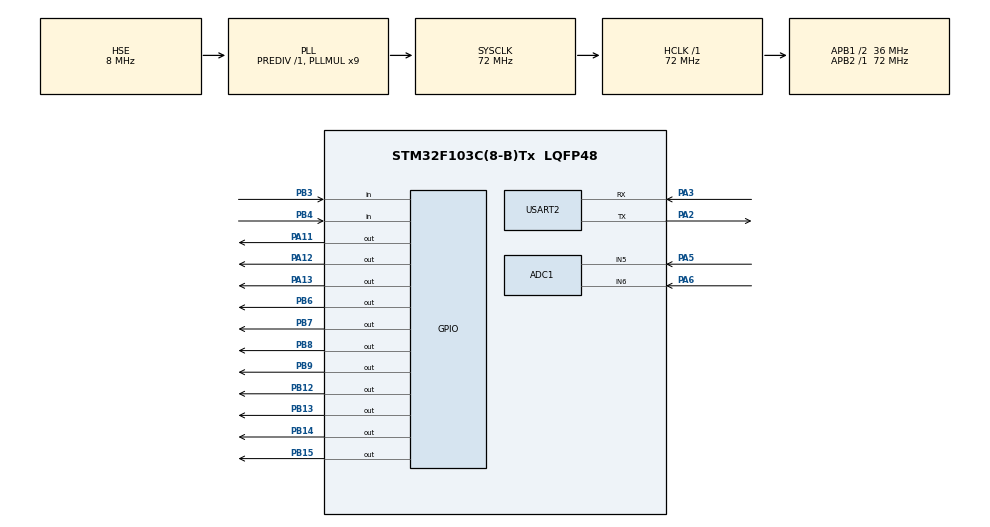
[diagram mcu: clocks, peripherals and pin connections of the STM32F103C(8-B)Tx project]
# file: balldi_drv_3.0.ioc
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ADC1.Channel-0\#ChannelRegularConversion=ADC_CHANNEL_5
ADC1.Channel-1\#ChannelRegularConversion=ADC_CHANNEL_6
ADC1.ContinuousConvMode=ENABLE
ADC1.NbrOfConversion=2
ADC1.NbrOfConversionFlag=1
ADC1.Rank-0\#ChannelRegularConversion=1
ADC1.Rank-1\#ChannelRegularConversion=2
ADC1.SamplingTime-0\#ChannelRegularConversion=ADC_SAMPLETIME_55CYCLES_5
ADC1.SamplingTime-1\#ChannelRegularConversion=ADC_SAMPLETIME_55CYCLES_5
ADC1.master=1
Dma.ADC1.2.Direction=DMA_PERIPH_TO_MEMORY
Dma.ADC1.2.Instance=DMA1_Channel1
Dma.ADC1.2.MemDataAlignment=DMA_MDATAALIGN_HALFWORD
Dma.ADC1.2.MemInc=DMA_MINC_ENABLE
Dma.ADC1.2.Mode=DMA_CIRCULAR
Dma.ADC1.2.PeriphDataAlignment=DMA_PDATAALIGN_HALFWORD
Dma.ADC1.2.PeriphInc=DMA_PINC_DISABLE
Dma.ADC1.2.Priority=DMA_PRIORITY_HIGH
Dma.Request0=USART2_RX
Dma.Request1=USART2_TX
Dma.Request2=ADC1
Dma.USART2_RX.0.Direction=DMA_PERIPH_TO_MEMORY
Dma.USART2_RX.0.Instance=DMA1_Channel6
Dma.USART2_RX.0.MemDataAlignment=DMA_MDATAALIGN_BYTE
Dma.USART2_RX.0.MemInc=DMA_MINC_ENABLE
Dma.USART2_RX.0.Mode=DMA_CIRCULAR
Dma.USART2_RX.0.PeriphDataAlignment=DMA_PDATAALIGN_BYTE
Dma.USART2_RX.0.PeriphInc=DMA_PINC_DISABLE
Dma.USART2_RX.0.Priority=DMA_PRIORITY_MEDIUM
Dma.USART2_TX.1.Direction=DMA_MEMORY_TO_PERIPH
Dma.USART2_TX.1.Instance=DMA1_Channel7
Dma.USART2_TX.1.MemDataAlignment=DMA_MDATAALIGN_BYTE
Dma.USART2_TX.1.MemInc=DMA_MINC_ENABLE
Dma.USART2_TX.1.Mode=DMA_NORMAL
Dma.USART2_TX.1.PeriphDataAlignment=DMA_PDATAALIGN_BYTE
Dma.USART2_TX.1.PeriphInc=DMA_PINC_DISABLE
Dma.USART2_TX.1.Priority=DMA_PRIORITY_MEDIUM
IWDG.Prescaler=IWDG_PRESCALER_256
IWDG.Reload=32
Mcu.Family=STM32F1
Mcu.Name=STM32F103C(8-B)Tx
Mcu.Package=LQFP48
NVIC.DMA1_Channel1_IRQn=true\:0\:0\:false\:false\:true\:false\:true\:true
NVIC.DMA1_Channel6_IRQn=true\:0\:0\:false\:false\:true\:false\:true\:true
NVIC.DMA1_Channel7_IRQn=true\:0\:0\:false\:false\:true\:false\:true\:true
NVIC.PriorityGroup=NVIC_PRIORITYGROUP_4
NVIC.TIM2_IRQn=true\:0\:0\:false\:false\:true\:true\:true\:true
NVIC.TIM4_IRQn=true\:0\:0\:false\:false\:true\:true\:true\:true
NVIC.USART2_IRQn=true\:0\:0\:false\:false\:true\:true\:true\:true
PA11.Signal=GPIO_Output
PA12.Signal=GPIO_Output
PA13.Signal=GPIO_Output
PA2.Mode=Asynchronous
PA2.Signal=USART2_TX
PA3.Mode=Asynchronous
PA3.Signal=USART2_RX
PA5.Signal=ADCx_IN5
PA6.Signal=ADCx_IN6
PB12.Signal=GPIO_Output
PB13.Signal=GPIO_Output
PB14.Signal=GPIO_Output
PB15.Signal=GPIO_Output
PB3.GPIO_PuPd=GPIO_NOPULL
PB3.Signal=GPIO_Input
PB4.GPIO_PuPd=GPIO_NOPULL
PB4.Signal=GPIO_Input
PB6.GPIO_Speed=GPIO_SPEED_FREQ_HIGH
PB6.Signal=GPIO_Output
PB7.GPIO_Speed=GPIO_SPEED_FREQ_HIGH
PB7.Signal=GPIO_Output
PB8.GPIO_Speed=GPIO_SPEED_FREQ_HIGH
PB8.PinState=GPIO_PIN_RESET
PB8.Signal=GPIO_Output
PB9.GPIO_Speed=GPIO_SPEED_FREQ_HIGH
PB9.Signal=GPIO_Output
PD0-OSC_IN.Mode=HSE-External-Oscillator
PD0-OSC_IN.Signal=RCC_OSC_IN
PD1-OSC_OUT.Mode=HSE-External-Oscillator
PD1-OSC_OUT.Signal=RCC_OSC_OUT
ProjectManager.HeapSize=0x200
ProjectManager.StackSize=0x400
ProjectManager.TargetToolchain=Makefile
RCC.ADCPresc=RCC_ADCPCLK2_DIV6
RCC.AHBFreq_Value=72000000
RCC.APB1CLKDivider=RCC_HCLK_DIV2
RCC.APB1Freq_Value=36000000
RCC.APB1TimFreq_Value=72000000
RCC.APB2Freq_Value=72000000
RCC.APB2TimFreq_Value=72000000
RCC.HCLKFreq_Value=72000000
RCC.PLLMUL=RCC_PLL_MUL9
RCC.PLLSourceVirtual=RCC_PLLSOURCE_HSE
RCC.SYSCLKFreq_VALUE=72000000
RCC.SYSCLKSource=RCC_SYSCLKSOURCE_PLLCLK
RCC.USBFreq_Value=72000000
SH.ADCx_IN5.0=ADC1_IN5,IN5
SH.ADCx_IN6.0=ADC1_IN6,IN6
TIM2.AutoReloadPreload=TIM_AUTORELOAD_PRELOAD_ENABLE
TIM2.Period=19
TIM2.Prescaler=71
TIM4.AutoReloadPreload=TIM_AUTORELOAD_PRELOAD_ENABLE
TIM4.Period=19
TIM4.Prescaler=71
USART2.VirtualMode=VM_ASYNC
VP_IWDG_VS_IWDG.Mode=IWDG_Activate
VP_SYS_VS_ND.Mode=No_Debug
VP_TIM2_VS_ClockSourceINT.Mode=Internal
VP_TIM4_VS_ClockSourceINT.Mode=Internal
board=custom

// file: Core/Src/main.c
/* USER CODE BEGIN Header */
/**
  ******************************************************************************
  * @file           : main.c
  * @brief          : Main program body
  ******************************************************************************
  * @attention
  *
  * Copyright (c) 2023 STMicroelectronics.
  * All rights reserved.
  *
  * This software is licensed under terms that can be found in the LICENSE file
  * in the root directory of this software component.
  * If no LICENSE file comes with this software, it is provided AS-IS.
  *
  ******************************************************************************
  */
/* USER CODE END Header */
#include "main.h"

/* USER CODE BEGIN Includes */
#include "private.h"
/* USER CODE END Includes */

ADC_HandleTypeDef hadc1;
DMA_HandleTypeDef hdma_adc1;

IWDG_HandleTypeDef hiwdg;

TIM_HandleTypeDef htim2;
TIM_HandleTypeDef htim4;

UART_HandleTypeDef huart2;
DMA_HandleTypeDef hdma_usart2_rx;
DMA_HandleTypeDef hdma_usart2_tx;

void SystemClock_Config(void);
static void MX_GPIO_Init(void);
static void MX_DMA_Init(void);
static void MX_TIM2_Init(void);
static void MX_TIM4_Init(void);
static void MX_ADC1_Init(void);
static void MX_USART2_UART_Init(void);
static void MX_IWDG_Init(void);

int main(void)
{

  /* MCU Configuration--------------------------------------------------------*/

  /* Reset of all peripherals, Initializes the Flash interface and the Systick. */
  HAL_Init();

  /* Configure the system clock */
  SystemClock_Config();

  /* Initialize all configured peripherals */
  MX_GPIO_Init();
  MX_DMA_Init();
  MX_TIM2_Init();
  MX_TIM4_Init();
  MX_ADC1_Init();
  MX_USART2_UART_Init();
  MX_IWDG_Init();
  /* USER CODE BEGIN 2 */

  usr_init_uart2_dma();
  usr_init_adc();

  HAL_TIM_Base_Start_IT(&htim2);
  HAL_TIM_Base_Start_IT(&htim4);

  /* USER CODE END 2 */

  /* Infinite loop */
  /* USER CODE BEGIN WHILE */

  //dbg_set_dir('f', 'b');
  //dbg_set_en('d', 'd');//pull high
  //dbg_set_speed(10, 55);

  while (1)
  {
    /* USER CODE END WHILE */

    /* USER CODE BEGIN 3 */
    FEED_DOG;
    usr_loop_uart2();

    usr_loop_smooth_movement();
    usr_loop_update_speed();
    usr_loop_update_dir();
    usr_loop_update_en();
    usr_loop_update_pwm_servo();
    usr_loop_update_adc();
    usr_loop_update_bat_status();

  }
  /* USER CODE END 3 */
}

void SystemClock_Config(void)
{
  RCC_OscInitTypeDef RCC_OscInitStruct = {0};
  RCC_ClkInitTypeDef RCC_ClkInitStruct = {0};
  RCC_PeriphCLKInitTypeDef PeriphClkInit = {0};

  /** Initializes the RCC Oscillators according to the specified parameters
  * in the RCC_OscInitTypeDef structure.
  */
  RCC_OscInitStruct.OscillatorType = RCC_OSCILLATORTYPE_LSI|RCC_OSCILLATORTYPE_HSE;
  RCC_OscInitStruct.HSEState = RCC_HSE_ON;
  RCC_OscInitStruct.HSEPredivValue = RCC_HSE_PREDIV_DIV1;
  RCC_OscInitStruct.HSIState = RCC_HSI_ON;
  RCC_OscInitStruct.LSIState = RCC_LSI_ON;
  RCC_OscInitStruct.PLL.PLLState = RCC_PLL_ON;
  RCC_OscInitStruct.PLL.PLLSource = RCC_PLLSOURCE_HSE;
  RCC_OscInitStruct.PLL.PLLMUL = RCC_PLL_MUL9;
  if (HAL_RCC_OscConfig(&RCC_OscInitStruct) != HAL_OK)
  {
    Error_Handler();
  }

  /** Initializes the CPU, AHB and APB buses clocks
  */
  RCC_ClkInitStruct.ClockType = RCC_CLOCKTYPE_HCLK|RCC_CLOCKTYPE_SYSCLK
                              |RCC_CLOCKTYPE_PCLK1|RCC_CLOCKTYPE_PCLK2;
  RCC_ClkInitStruct.SYSCLKSource = RCC_SYSCLKSOURCE_PLLCLK;
  RCC_ClkInitStruct.AHBCLKDivider = RCC_SYSCLK_DIV1;
  RCC_ClkInitStruct.APB1CLKDivider = RCC_HCLK_DIV2;
  RCC_ClkInitStruct.APB2CLKDivider = RCC_HCLK_DIV1;

  if (HAL_RCC_ClockConfig(&RCC_ClkInitStruct, FLASH_LATENCY_2) != HAL_OK)
  {
    Error_Handler();
  }
  PeriphClkInit.PeriphClockSelection = RCC_PERIPHCLK_ADC;
  PeriphClkInit.AdcClockSelection = RCC_ADCPCLK2_DIV6;
  if (HAL_RCCEx_PeriphCLKConfig(&PeriphClkInit) != HAL_OK)
  {
    Error_Handler();
  }
}

static void MX_ADC1_Init(void)
{

  ADC_ChannelConfTypeDef sConfig = {0};

  /** Common config
  */
  hadc1.Instance = ADC1;
  hadc1.Init.ScanConvMode = ADC_SCAN_ENABLE;
  hadc1.Init.ContinuousConvMode = ENABLE;
  hadc1.Init.DiscontinuousConvMode = DISABLE;
  hadc1.Init.ExternalTrigConv = ADC_SOFTWARE_START;
  hadc1.Init.DataAlign = ADC_DATAALIGN_RIGHT;
  hadc1.Init.NbrOfConversion = 2;
  if (HAL_ADC_Init(&hadc1) != HAL_OK)
  {
    Error_Handler();
  }

  /** Configure Regular Channel
  */
  sConfig.Channel = ADC_CHANNEL_5;
  sConfig.Rank = ADC_REGULAR_RANK_1;
  sConfig.SamplingTime = ADC_SAMPLETIME_55CYCLES_5;
  if (HAL_ADC_ConfigChannel(&hadc1, &sConfig) != HAL_OK)
  {
    Error_Handler();
  }

  /** Configure Regular Channel
  */
  sConfig.Channel = ADC_CHANNEL_6;
  sConfig.Rank = ADC_REGULAR_RANK_2;
  if (HAL_ADC_ConfigChannel(&hadc1, &sConfig) != HAL_OK)
  {
    Error_Handler();
  }

}

static void MX_IWDG_Init(void)
{

  hiwdg.Instance = IWDG;
  hiwdg.Init.Prescaler = IWDG_PRESCALER_256;
  hiwdg.Init.Reload = 32;
  if (HAL_IWDG_Init(&hiwdg) != HAL_OK)
  {
    Error_Handler();
  }

}

static void MX_TIM2_Init(void)
{

  TIM_ClockConfigTypeDef sClockSourceConfig = {0};
  TIM_MasterConfigTypeDef sMasterConfig = {0};

  htim2.Instance = TIM2;
  htim2.Init.Prescaler = 71;
  htim2.Init.CounterMode = TIM_COUNTERMODE_UP;
  htim2.Init.Period = 19;
  htim2.Init.ClockDivision = TIM_CLOCKDIVISION_DIV1;
  htim2.Init.AutoReloadPreload = TIM_AUTORELOAD_PRELOAD_ENABLE;
  if (HAL_TIM_Base_Init(&htim2) != HAL_OK)
  {
    Error_Handler();
  }
  sClockSourceConfig.ClockSource = TIM_CLOCKSOURCE_INTERNAL;
  if (HAL_TIM_ConfigClockSource(&htim2, &sClockSourceConfig) != HAL_OK)
  {
    Error_Handler();
  }
  sMasterConfig.MasterOutputTrigger = TIM_TRGO_RESET;
  sMasterConfig.MasterSlaveMode = TIM_MASTERSLAVEMODE_DISABLE;
  if (HAL_TIMEx_MasterConfigSynchronization(&htim2, &sMasterConfig) != HAL_OK)
  {
    Error_Handler();
  }

}

static void MX_TIM4_Init(void)
{

  TIM_ClockConfigTypeDef sClockSourceConfig = {0};
  TIM_MasterConfigTypeDef sMasterConfig = {0};

  htim4.Instance = TIM4;
  htim4.Init.Prescaler = 71;
  htim4.Init.CounterMode = TIM_COUNTERMODE_UP;
  htim4.Init.Period = 19;
  htim4.Init.ClockDivision = TIM_CLOCKDIVISION_DIV1;
  htim4.Init.AutoReloadPreload = TIM_AUTORELOAD_PRELOAD_ENABLE;
  if (HAL_TIM_Base_Init(&htim4) != HAL_OK)
  {
    Error_Handler();
  }
  sClockSourceConfig.ClockSource = TIM_CLOCKSOURCE_INTERNAL;
  if (HAL_TIM_ConfigClockSource(&htim4, &sClockSourceConfig) != HAL_OK)
  {
    Error_Handler();
  }
  sMasterConfig.MasterOutputTrigger = TIM_TRGO_RESET;
  sMasterConfig.MasterSlaveMode = TIM_MASTERSLAVEMODE_DISABLE;
  if (HAL_TIMEx_MasterConfigSynchronization(&htim4, &sMasterConfig) != HAL_OK)
  {
    Error_Handler();
  }

}

static void MX_USART2_UART_Init(void)
{

  huart2.Instance = USART2;
  huart2.Init.BaudRate = 115200;
  huart2.Init.WordLength = UART_WORDLENGTH_8B;
  huart2.Init.StopBits = UART_STOPBITS_1;
  huart2.Init.Parity = UART_PARITY_NONE;
  huart2.Init.Mode = UART_MODE_TX_RX;
  huart2.Init.HwFlowCtl = UART_HWCONTROL_NONE;
  huart2.Init.OverSampling = UART_OVERSAMPLING_16;
  if (HAL_UART_Init(&huart2) != HAL_OK)
  {
    Error_Handler();
  }

}

static void MX_DMA_Init(void)
{

  /* DMA controller clock enable */
  __HAL_RCC_DMA1_CLK_ENABLE();

  /* DMA interrupt init */
  /* DMA1_Channel1_IRQn interrupt configuration */
  HAL_NVIC_SetPriority(DMA1_Channel1_IRQn, 0, 0);
  HAL_NVIC_EnableIRQ(DMA1_Channel1_IRQn);
  /* DMA1_Channel6_IRQn interrupt configuration */
  HAL_NVIC_SetPriority(DMA1_Channel6_IRQn, 0, 0);
  HAL_NVIC_EnableIRQ(DMA1_Channel6_IRQn);
  /* DMA1_Channel7_IRQn interrupt configuration */
  HAL_NVIC_SetPriority(DMA1_Channel7_IRQn, 0, 0);
  HAL_NVIC_EnableIRQ(DMA1_Channel7_IRQn);

}

static void MX_GPIO_Init(void)
{
  GPIO_InitTypeDef GPIO_InitStruct = {0};

  /* GPIO Ports Clock Enable */
  __HAL_RCC_GPIOD_CLK_ENABLE();
  __HAL_RCC_GPIOA_CLK_ENABLE();
  __HAL_RCC_GPIOB_CLK_ENABLE();

  /*Configure GPIO pin Output Level */
  HAL_GPIO_WritePin(GPIOB, GPIO_PIN_12|GPIO_PIN_13|GPIO_PIN_14|GPIO_PIN_15
                          |GPIO_PIN_6|GPIO_PIN_7|GPIO_PIN_8|GPIO_PIN_9, GPIO_PIN_RESET);

  /*Configure GPIO pin Output Level */
  HAL_GPIO_WritePin(GPIOA, GPIO_PIN_11|GPIO_PIN_12|GPIO_PIN_13, GPIO_PIN_RESET);

  /*Configure GPIO pins : PB12 PB13 PB14 PB15 */
  GPIO_InitStruct.Pin = GPIO_PIN_12|GPIO_PIN_13|GPIO_PIN_14|GPIO_PIN_15;
  GPIO_InitStruct.Mode = GPIO_MODE_OUTPUT_PP;
  GPIO_InitStruct.Pull = GPIO_NOPULL;
  GPIO_InitStruct.Speed = GPIO_SPEED_FREQ_LOW;
  HAL_GPIO_Init(GPIOB, &GPIO_InitStruct);

  /*Configure GPIO pins : PA11 PA12 PA13 */
  GPIO_InitStruct.Pin = GPIO_PIN_11|GPIO_PIN_12|GPIO_PIN_13;
  GPIO_InitStruct.Mode = GPIO_MODE_OUTPUT_PP;
  GPIO_InitStruct.Pull = GPIO_NOPULL;
  GPIO_InitStruct.Speed = GPIO_SPEED_FREQ_LOW;
  HAL_GPIO_Init(GPIOA, &GPIO_InitStruct);

  /*Configure GPIO pins : PB3 PB4 */
  GPIO_InitStruct.Pin = GPIO_PIN_3|GPIO_PIN_4;
  GPIO_InitStruct.Mode = GPIO_MODE_INPUT;
  GPIO_InitStruct.Pull = GPIO_NOPULL;
  HAL_GPIO_Init(GPIOB, &GPIO_InitStruct);

  /*Configure GPIO pins : PB6 PB7 PB8 PB9 */
  GPIO_InitStruct.Pin = GPIO_PIN_6|GPIO_PIN_7|GPIO_PIN_8|GPIO_PIN_9;
  GPIO_InitStruct.Mode = GPIO_MODE_OUTPUT_PP;
  GPIO_InitStruct.Pull = GPIO_NOPULL;
  GPIO_InitStruct.Speed = GPIO_SPEED_FREQ_HIGH;
  HAL_GPIO_Init(GPIOB, &GPIO_InitStruct);

}

void Error_Handler(void)
{
  __disable_irq();
  while (1)
  {
  }
}
